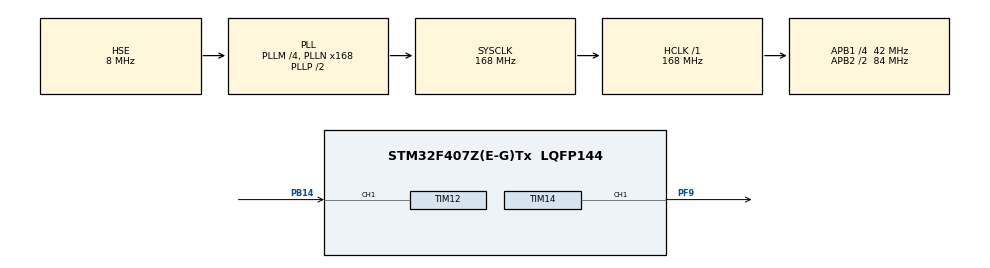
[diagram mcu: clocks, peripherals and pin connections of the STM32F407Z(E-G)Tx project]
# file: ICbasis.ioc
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Mcu.Family=STM32F4
Mcu.Name=STM32F407Z(E-G)Tx
Mcu.Package=LQFP144
NVIC.PriorityGroup=NVIC_PRIORITYGROUP_4
NVIC.TIM8_BRK_TIM12_IRQn=true\:0\:0\:false\:false\:true\:true\:true\:true
PA13.Mode=Serial_Wire
PA13.Signal=SYS_JTMS-SWDIO
PA14.Mode=Serial_Wire
PA14.Signal=SYS_JTCK-SWCLK
PB14.Signal=S_TIM12_CH1
PF9.Signal=S_TIM14_CH1
PH0-OSC_IN.Mode=HSE-External-Oscillator
PH0-OSC_IN.Signal=RCC_OSC_IN
PH1-OSC_OUT.Mode=HSE-External-Oscillator
PH1-OSC_OUT.Signal=RCC_OSC_OUT
ProjectManager.HeapSize=0x200
ProjectManager.StackSize=0x400
ProjectManager.TargetToolchain=STM32CubeIDE
RCC.48MHZClocksFreq_Value=84000000
RCC.AHBFreq_Value=168000000
RCC.APB1CLKDivider=RCC_HCLK_DIV4
RCC.APB1Freq_Value=42000000
RCC.APB1TimFreq_Value=84000000
RCC.APB2CLKDivider=RCC_HCLK_DIV2
RCC.APB2Freq_Value=84000000
RCC.APB2TimFreq_Value=168000000
RCC.CortexFreq_Value=168000000
RCC.HCLKFreq_Value=168000000
RCC.HSE_VALUE=8000000
RCC.HSI_VALUE=16000000
RCC.LSE_VALUE=32768
RCC.PLLM=4
RCC.PLLN=168
RCC.PLLSourceVirtual=RCC_PLLSOURCE_HSE
RCC.SYSCLKFreq_VALUE=168000000
RCC.SYSCLKSource=RCC_SYSCLKSOURCE_PLLCLK
RCC.VCOOutputFreq_Value=336000000
SH.S_TIM12_CH1.0=TIM12_CH1,TriggerSource_TI1FP1
SH.S_TIM12_CH1.1=TIM12_CH1,Input_Capture1_from_TI1
SH.S_TIM14_CH1.0=TIM14_CH1,PWM Generation1 CH1
TIM12.Channel-Input_Capture1_from_TI1=TIM_CHANNEL_1
TIM12.Channel-Input_Capture2_from_TI1_63=TIM_CHANNEL_2
TIM12.ICPolarity_CH1=TIM_INPUTCHANNELPOLARITY_FALLING
TIM12.Prescaler=419
TIM14.Channel=TIM_CHANNEL_1
TIM14.OCMode_PWM=TIM_OCMODE_PWM2
TIM14.Prescaler=419
VP_TIM12_VS_ClockSourceINT.Mode=Internal
VP_TIM12_VS_ControllerModeReset.Mode=Reset Mode
VP_TIM12_VS_indirect_ch1.Mode=Input_Capture2_from_TI1_63
VP_TIM14_VS_ClockSourceINT.Mode=Enable_Timer
board=custom

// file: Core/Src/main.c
/* USER CODE BEGIN Header */
/**
  ******************************************************************************
  * @file           : main.c
  * @brief          : Main program body
  ******************************************************************************
  * @attention
  *
  * Copyright (c) 2024 STMicroelectronics.
  * All rights reserved.
  *
  * This software is licensed under terms that can be found in the LICENSE file
  * in the root directory of this software component.
  * If no LICENSE file comes with this software, it is provided AS-IS.
  *
  ******************************************************************************
  */
/* USER CODE END Header */
#include "main.h"

/* USER CODE BEGIN PTD */

typedef struct{

	uint16_t duty;
	uint16_t frequency;

}CAP_TIM_VAR_type;

CAP_TIM_VAR_type CAP_TIM_VAR;

/* USER CODE END PTD */

TIM_HandleTypeDef htim12;
TIM_HandleTypeDef htim14;

void SystemClock_Config(void);
static void MX_GPIO_Init(void);
static void MX_TIM14_Init(void);
static void MX_TIM12_Init(void);

/* USER CODE BEGIN 0 */

uint16_t duty;
uint16_t frequency;

uint16_t CAP_Readfrequency(void){

	uint16_t frequency = 0;
	frequency = CAP_TIM_VAR.frequency;
	CAP_TIM_VAR.frequency = 0;

	return(frequency);

}

uint16_t CAP_Readduty(void){

	uint16_t duty = 0;
	duty = CAP_TIM_VAR.duty;
	CAP_TIM_VAR.duty = 0;

	return(duty);

}

/* USER CODE END 0 */

int main(void)
{

  /* MCU Configuration--------------------------------------------------------*/

  /* Reset of all peripherals, Initializes the Flash interface and the Systick. */
  HAL_Init();

  /* Configure the system clock */
  SystemClock_Config();

  /* Initialize all configured peripherals */
  MX_GPIO_Init();
  MX_TIM14_Init();
  MX_TIM12_Init();
  /* USER CODE BEGIN 2 */

  HAL_TIM_PWM_Start(&htim14, TIM_CHANNEL_1);
  __HAL_TIM_SET_AUTORELOAD(&htim14, 2000);

  __HAL_TIM_SET_COMPARE(&htim14, TIM_CHANNEL_1, 600);
  HAL_Delay(100);

  HAL_TIM_IC_Start_IT(&htim12, TIM_CHANNEL_1);
  HAL_TIM_IC_Start(&htim12, TIM_CHANNEL_2);

  /* USER CODE END 2 */

  /* Infinite loop */
  while (1)
  {
	  HAL_Delay(50);
	  frequency = CAP_Readfrequency();
	  duty = CAP_Readduty();

  }
}

void SystemClock_Config(void)
{
  RCC_OscInitTypeDef RCC_OscInitStruct = {0};
  RCC_ClkInitTypeDef RCC_ClkInitStruct = {0};

  /** Configure the main internal regulator output voltage
  */
  __HAL_RCC_PWR_CLK_ENABLE();
  __HAL_PWR_VOLTAGESCALING_CONFIG(PWR_REGULATOR_VOLTAGE_SCALE1);

  /** Initializes the RCC Oscillators according to the specified parameters
  * in the RCC_OscInitTypeDef structure.
  */
  RCC_OscInitStruct.OscillatorType = RCC_OSCILLATORTYPE_HSE;
  RCC_OscInitStruct.HSEState = RCC_HSE_ON;
  RCC_OscInitStruct.PLL.PLLState = RCC_PLL_ON;
  RCC_OscInitStruct.PLL.PLLSource = RCC_PLLSOURCE_HSE;
  RCC_OscInitStruct.PLL.PLLM = 4;
  RCC_OscInitStruct.PLL.PLLN = 168;
  RCC_OscInitStruct.PLL.PLLP = RCC_PLLP_DIV2;
  RCC_OscInitStruct.PLL.PLLQ = 4;
  if (HAL_RCC_OscConfig(&RCC_OscInitStruct) != HAL_OK)
  {
    Error_Handler();
  }

  /** Initializes the CPU, AHB and APB buses clocks
  */
  RCC_ClkInitStruct.ClockType = RCC_CLOCKTYPE_HCLK|RCC_CLOCKTYPE_SYSCLK
                              |RCC_CLOCKTYPE_PCLK1|RCC_CLOCKTYPE_PCLK2;
  RCC_ClkInitStruct.SYSCLKSource = RCC_SYSCLKSOURCE_PLLCLK;
  RCC_ClkInitStruct.AHBCLKDivider = RCC_SYSCLK_DIV1;
  RCC_ClkInitStruct.APB1CLKDivider = RCC_HCLK_DIV4;
  RCC_ClkInitStruct.APB2CLKDivider = RCC_HCLK_DIV2;

  if (HAL_RCC_ClockConfig(&RCC_ClkInitStruct, FLASH_LATENCY_5) != HAL_OK)
  {
    Error_Handler();
  }
}

static void MX_TIM12_Init(void)
{

  TIM_ClockConfigTypeDef sClockSourceConfig = {0};
  TIM_SlaveConfigTypeDef sSlaveConfig = {0};
  TIM_IC_InitTypeDef sConfigIC = {0};

  htim12.Instance = TIM12;
  htim12.Init.Prescaler = 419;
  htim12.Init.CounterMode = TIM_COUNTERMODE_UP;
  htim12.Init.Period = 65535;
  htim12.Init.ClockDivision = TIM_CLOCKDIVISION_DIV1;
  htim12.Init.AutoReloadPreload = TIM_AUTORELOAD_PRELOAD_DISABLE;
  if (HAL_TIM_Base_Init(&htim12) != HAL_OK)
  {
    Error_Handler();
  }
  sClockSourceConfig.ClockSource = TIM_CLOCKSOURCE_INTERNAL;
  if (HAL_TIM_ConfigClockSource(&htim12, &sClockSourceConfig) != HAL_OK)
  {
    Error_Handler();
  }
  if (HAL_TIM_IC_Init(&htim12) != HAL_OK)
  {
    Error_Handler();
  }
  sSlaveConfig.SlaveMode = TIM_SLAVEMODE_RESET;
  sSlaveConfig.InputTrigger = TIM_TS_TI1FP1;
  sSlaveConfig.TriggerPolarity = TIM_INPUTCHANNELPOLARITY_FALLING;
  sSlaveConfig.TriggerFilter = 0;
  if (HAL_TIM_SlaveConfigSynchro(&htim12, &sSlaveConfig) != HAL_OK)
  {
    Error_Handler();
  }
  sConfigIC.ICPolarity = TIM_INPUTCHANNELPOLARITY_FALLING;
  sConfigIC.ICSelection = TIM_ICSELECTION_DIRECTTI;
  sConfigIC.ICPrescaler = TIM_ICPSC_DIV1;
  sConfigIC.ICFilter = 0;
  if (HAL_TIM_IC_ConfigChannel(&htim12, &sConfigIC, TIM_CHANNEL_1) != HAL_OK)
  {
    Error_Handler();
  }
  sConfigIC.ICPolarity = TIM_INPUTCHANNELPOLARITY_RISING;
  sConfigIC.ICSelection = TIM_ICSELECTION_INDIRECTTI;
  if (HAL_TIM_IC_ConfigChannel(&htim12, &sConfigIC, TIM_CHANNEL_2) != HAL_OK)
  {
    Error_Handler();
  }

}

static void MX_TIM14_Init(void)
{

  TIM_OC_InitTypeDef sConfigOC = {0};

  htim14.Instance = TIM14;
  htim14.Init.Prescaler = 419;
  htim14.Init.CounterMode = TIM_COUNTERMODE_UP;
  htim14.Init.Period = 65535;
  htim14.Init.ClockDivision = TIM_CLOCKDIVISION_DIV1;
  htim14.Init.AutoReloadPreload = TIM_AUTORELOAD_PRELOAD_DISABLE;
  if (HAL_TIM_Base_Init(&htim14) != HAL_OK)
  {
    Error_Handler();
  }
  if (HAL_TIM_PWM_Init(&htim14) != HAL_OK)
  {
    Error_Handler();
  }
  sConfigOC.OCMode = TIM_OCMODE_PWM2;
  sConfigOC.Pulse = 0;
  sConfigOC.OCPolarity = TIM_OCPOLARITY_HIGH;
  sConfigOC.OCFastMode = TIM_OCFAST_DISABLE;
  if (HAL_TIM_PWM_ConfigChannel(&htim14, &sConfigOC, TIM_CHANNEL_1) != HAL_OK)
  {
    Error_Handler();
  }
  HAL_TIM_MspPostInit(&htim14);

}

static void MX_GPIO_Init(void)
{

  /* GPIO Ports Clock Enable */
  __HAL_RCC_GPIOF_CLK_ENABLE();
  __HAL_RCC_GPIOH_CLK_ENABLE();
  __HAL_RCC_GPIOB_CLK_ENABLE();
  __HAL_RCC_GPIOA_CLK_ENABLE();

}

/* USER CODE BEGIN 4 */

void HAL_TIM_IC_CaptureCallback(TIM_HandleTypeDef *htim){

	if(htim->Instance == TIM12){
		CAP_TIM_VAR.frequency = __HAL_TIM_GET_COMPARE(&htim12, TIM_CHANNEL_1);
		CAP_TIM_VAR.duty = __HAL_TIM_GET_COMPARE(&htim12, TIM_CHANNEL_2);
	}

}

/* USER CODE END 4 */

void Error_Handler(void)
{
  __disable_irq();
  while (1)
  {
  }
}
